# MB9BF56xx register map
File version: 1.0
Registers are 8-bit, read-write, reset 0x0 unless marked. A register's access mark holds for its fields unless they carry their own. Offsets are from the block's base; [hi:lo] are bit positions; {n}, {i} and the like mark numbered series; 'fields as' and 'values as' point back to an identical list.

## MFT0 — peripheral MFT0
Base 0x40020000
Same registers: MFT1 0x40021000, MFT2 0x40022000
{0x102+4i} OCU_OCCP{i} 16-bit (i=0..5)
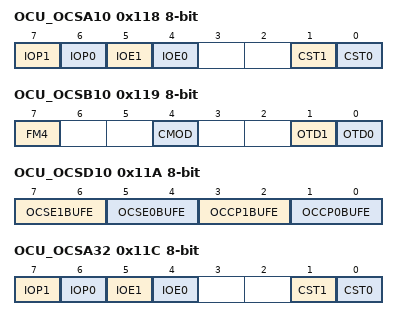
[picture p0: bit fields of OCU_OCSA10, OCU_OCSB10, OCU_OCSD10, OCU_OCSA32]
0x118 OCU_OCSA10
  [7] IOP1, [6] IOP0, [5] IOE1, [4] IOE0, [1] CST1, [0] CST0
0x119 OCU_OCSB10
  [7] FM4, [4] CMOD, [1] OTD1, [0] OTD0
0x11A OCU_OCSD10
  [7:6] OCSE1BUFE, [5:4] OCSE0BUFE, [3:2] OCCP1BUFE, [1:0] OCCP0BUFE
0x11C OCU_OCSA32
  [7] IOP1, [6] IOP0, [5] IOE1, [4] IOE0, [1] CST1, [0] CST0
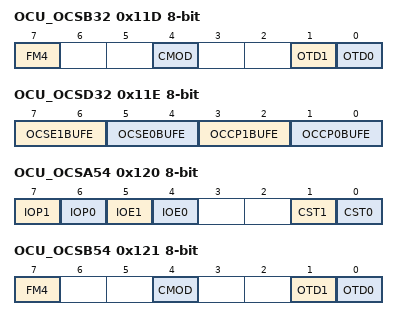
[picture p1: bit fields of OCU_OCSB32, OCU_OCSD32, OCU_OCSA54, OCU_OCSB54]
0x11D OCU_OCSB32
  [7] FM4, [4] CMOD, [1] OTD1, [0] OTD0
0x11E OCU_OCSD32
  [7:6] OCSE1BUFE, [5:4] OCSE0BUFE, [3:2] OCCP1BUFE, [1:0] OCCP0BUFE
0x120 OCU_OCSA54
  [7] IOP1, [6] IOP0, [5] IOE1, [4] IOE0, [1] CST1, [0] CST0
0x121 OCU_OCSB54
  [7] FM4, [4] CMOD, [1] OTD1, [0] OTD0
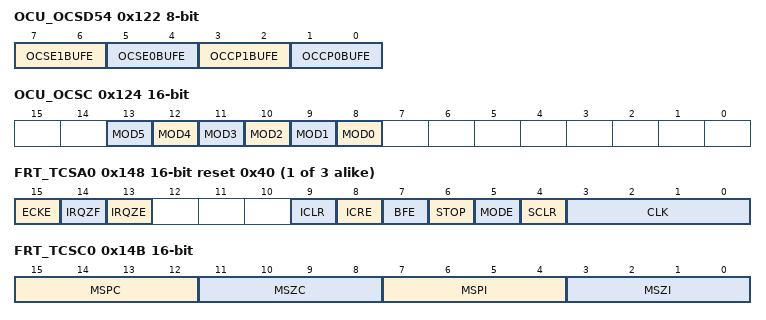
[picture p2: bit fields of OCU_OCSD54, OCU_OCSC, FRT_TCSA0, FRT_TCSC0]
0x122 OCU_OCSD54
  [7:6] OCSE1BUFE, [5:4] OCSE0BUFE, [3:2] OCCP1BUFE, [1:0] OCCP0BUFE
0x124 OCU_OCSC 16-bit
  [n+8] MOD{n} (n=0..5)
0x128 OCU_OCSE0
  [7:0] OCSE
0x12C OCU_OCSE1 16-bit
  [15:0] OCSE
0x130 OCU_OCSE2
  [7:0] OCSE
0x134 OCU_OCSE3 16-bit
  [15:0] OCSE
0x138 OCU_OCSE4
  [7:0] OCSE
0x13C OCU_OCSE5 16-bit
  [15:0] OCSE
{0x142+0xC*i} FRT_TCCP{i} 16-bit reset 0xFFFF (i=0..2)
{0x146+0xC*i} FRT_TCDT{i} 16-bit (i=0..2)
{0x148+0xC*i} FRT_TCSA{i} 16-bit reset 0x40 (i=0..2)
  [15] ECKE, [14] IRQZF, [13] IRQZE, [9] ICLR, [8] ICRE, [7] BFE, [6] STOP, [5] MODE, [4] SCLR wo, [3:0] CLK
0x14B FRT_TCSC0 16-bit
  [15:12] MSPC ro, [11:8] MSZC ro, [7:4] MSPI, [3:0] MSZI
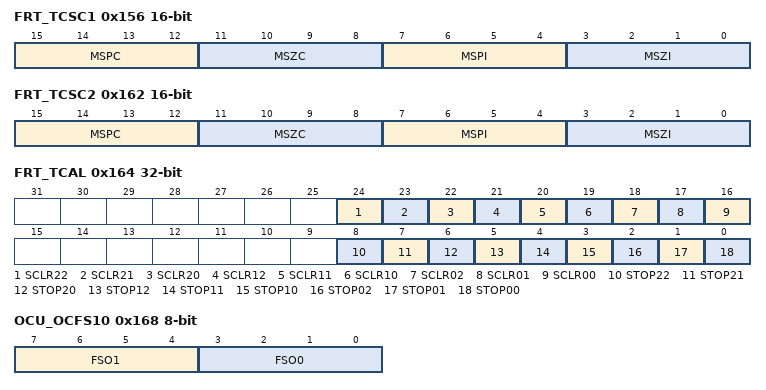
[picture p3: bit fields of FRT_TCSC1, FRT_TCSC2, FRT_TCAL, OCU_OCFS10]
0x156 FRT_TCSC1 16-bit
  [15:12] MSPC ro, [11:8] MSZC ro, [7:4] MSPI, [3:0] MSZI
0x162 FRT_TCSC2 16-bit
  [15:12] MSPC ro, [11:8] MSZC ro, [7:4] MSPI, [3:0] MSZI
0x164 FRT_TCAL 32-bit (reset mask 0xFFFF)
  [24] SCLR22 wo, [23] SCLR21 wo, [22] SCLR20 wo, [21] SCLR12 wo, [20] SCLR11 wo, [19] SCLR10 wo, [18] SCLR02 wo, [17] SCLR01 wo, [16] SCLR00 wo, [8] STOP22, [7] STOP21, [6] STOP20, [5] STOP12, [4] STOP11, [3] STOP10, [2] STOP02, [1] STOP01, [0] STOP00
0x168 OCU_OCFS10
  [7:4] FSO1, [3:0] FSO0
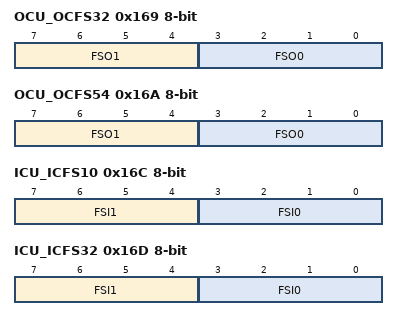
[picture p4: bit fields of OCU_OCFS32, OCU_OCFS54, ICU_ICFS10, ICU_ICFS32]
0x169 OCU_OCFS32
  [7:4] FSO1, [3:0] FSO0
0x16A OCU_OCFS54
  [7:4] FSO1, [3:0] FSO0
0x16C ICU_ICFS10
  [7:4] FSI1, [3:0] FSI0
0x16D ICU_ICFS32
  [7:4] FSI1, [3:0] FSI0
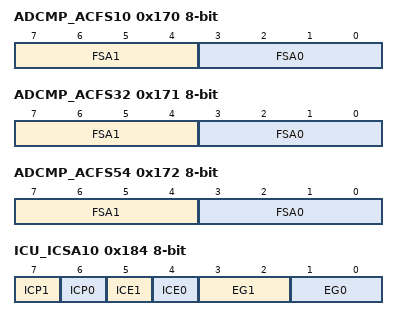
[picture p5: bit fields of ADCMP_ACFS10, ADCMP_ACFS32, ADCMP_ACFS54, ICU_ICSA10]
0x170 ADCMP_ACFS10
  [7:4] FSA1, [3:0] FSA0
0x171 ADCMP_ACFS32
  [7:4] FSA1, [3:0] FSA0
0x172 ADCMP_ACFS54
  [7:4] FSA1, [3:0] FSA0
{0x176+4i} ICU_ICCP{i} 16-bit ro reset not defined (i=0..3)
0x184 ICU_ICSA10
  [7] ICP1, [6] ICP0, [5] ICE1, [4] ICE0, [3:2] EG1, [1:0] EG0
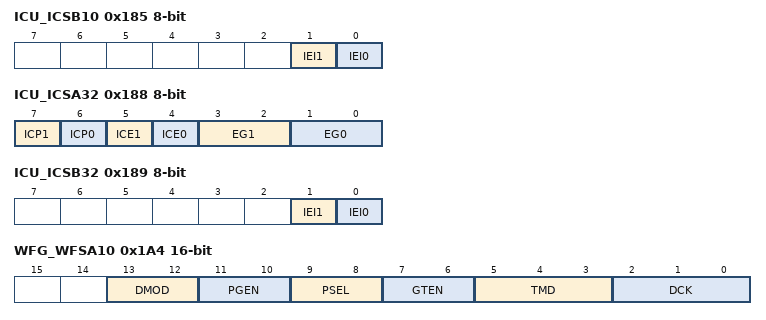
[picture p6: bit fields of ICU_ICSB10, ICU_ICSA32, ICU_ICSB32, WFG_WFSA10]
0x185 ICU_ICSB10 ro
  [1] IEI1, [0] IEI0
0x188 ICU_ICSA32
  [7] ICP1, [6] ICP0, [5] ICE1, [4] ICE0, [3:2] EG1, [1:0] EG0
0x189 ICU_ICSB32 ro
  [1] IEI1, [0] IEI0
0x18E WFG_WFTF10 16-bit
0x190 WFG_WFTA10
0x192 WFG_WFTB10
0x196 WFG_WFTF32 16-bit
0x198 WFG_WFTA32
0x19A WFG_WFTB32
0x19E WFG_WFTF54 16-bit
0x1A0 WFG_WFTA54
0x1A2 WFG_WFTB54
0x1A4 WFG_WFSA10 16-bit
  [13:12] DMOD, [11:10] PGEN, [9:8] PSEL, [7:6] GTEN, [5:3] TMD, [2:0] DCK
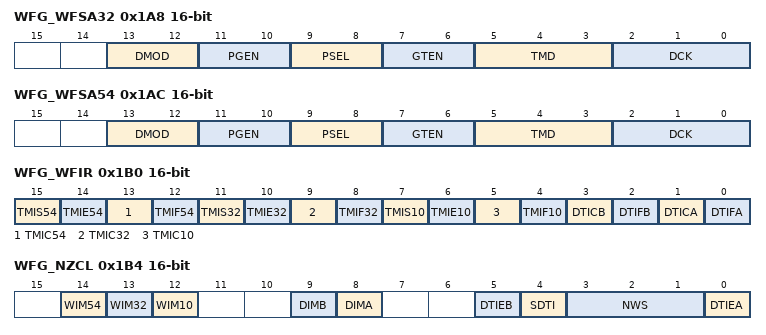
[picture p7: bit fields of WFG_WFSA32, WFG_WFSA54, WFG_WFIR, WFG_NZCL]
0x1A8 WFG_WFSA32 16-bit
  fields as WFG_WFSA10
0x1AC WFG_WFSA54 16-bit
  fields as WFG_WFSA10
0x1B0 WFG_WFIR 16-bit
  [15] TMIS54 wo, [14] TMIE54, [13] TMIC54 wo, [12] TMIF54 ro, [11] TMIS32 wo, [10] TMIE32, [9] TMIC32 wo, [8] TMIF32 ro, [7] TMIS10 wo, [6] TMIE10, [5] TMIC10 wo, [4] TMIF10 ro, [3] DTICB wo, [2] DTIFB ro, [1] DTICA wo, [0] DTIFA ro
0x1B4 WFG_NZCL 16-bit
  [14] WIM54, [13] WIM32, [12] WIM10, [9] DIMB, [8] DIMA, [5] DTIEB, [4] SDTI wo, [3:1] NWS, [0] DTIEA
{0x1BA+4i} ADCMP_ACMP{i} 16-bit (i=0..5)
  [15:0] ACMP
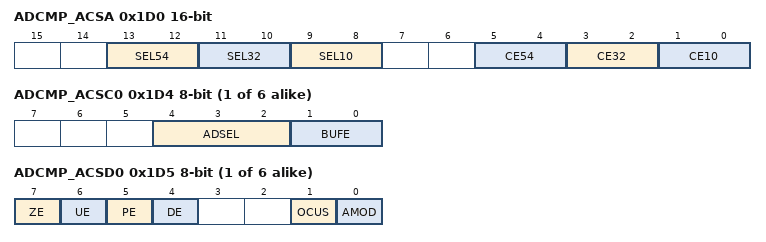
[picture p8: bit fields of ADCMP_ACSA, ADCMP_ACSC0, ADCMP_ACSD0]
0x1D0 ADCMP_ACSA 16-bit
  [13:12] SEL54, [11:10] SEL32, [9:8] SEL10, [5:4] CE54, [3:2] CE32, [1:0] CE10
{0x1D4+4i} ADCMP_ACSC{i} (i=0..5)
  [4:2] ADSEL, [1:0] BUFE
{0x1D5+4i} ADCMP_ACSD{i} (i=0..5)
  [7] ZE, [6] UE, [5] PE, [4] DE, [1] OCUS, [0] AMOD

## BTIOSEL03 — peripheral BTIOSEL03
Base 0x40025100
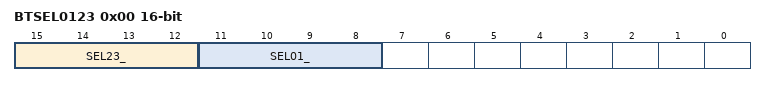
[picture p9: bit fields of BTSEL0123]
0x00 BTSEL0123 16-bit
  [15:12] SEL23_, [11:8] SEL01_

## BTIOSEL47 — peripheral BTIOSEL47
Base 0x40025300
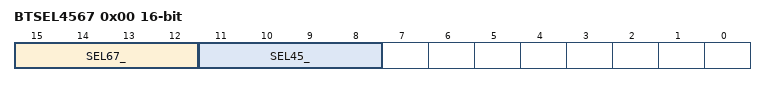
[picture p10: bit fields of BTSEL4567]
0x00 BTSEL4567 16-bit
  [15:12] SEL67_, [11:8] SEL45_

## Notices in the file
Licence Terms
FUJITSU SEMICONDUCTOR LIMITED (gLICENSORh) hereby grants and
you (gLICENSEEh) hereby accept a non transferable, non-exclusive
licence to use and copy the deliverables (gDeliverablesh) solely for
the purpose of; (i) developing LICENSEEfs development tools and
distributing such development tools to third parties; (ii) generating
derivative representations of the Deliverables to develop and debug
software for LICENSORfs targeted devices or device series identified
within the Deliverables, (together the gPurposeh) under the following
terms and conditions:
1. Ownership.
The Deliverables are the property of LICENSOR. LICENSEE acquires no
right, title or interest in the Deliverables other than the licence
rights granted herein.
2. Use.
LICENSEE shall only be permitted to use the Deliverables for the
Purpose. LICENSEE shall not reverse engineer, decompile or
disassemble the Deliverables, in whole or in part.
3. Copies.
All copies of the Deliverables must bear the same notice(s) contained
on the original copies of the Deliverables.
4. No Warranty.
THE DELIVERABLES ARE PROVIDED gAS ISh AND ANY EXPRESS, IMPLIED OR
STATUTORY WARRANTIES, INCLUDING, BUT NOT LIMITED TO, THE IMPLIED
WARRANTIES OF MERCHANTABILITY, SATISFACTORY QUALITY AND FITNESS FOR
A PARTICULAR PURPOSE ARE DISCLAIMED.
IN NO EVENT SHALL LICENSOR BE LIABLE FOR ANY DIRECT, INDIRECT,
INCIDENTAL, SPECIAL, EXEMPLARY, OR CONSEQUENTIAL DAMAGES HOWEVER CAUSED
AND ON ANY THEORY OF LIABILITY, WHETHER IN CONTRACT, STRICT LIABILITY,
OR TORT (INCLUDING NEGLIGENCE OR OTHERWISE) ARISING IN ANY WAY OUT OF
THE USE OF THE DELIVERABLES, EVEN IF ADVISED OF THE POSSIBILITY OF SUCH
DAMAGE.
LICENSEE EXPRESSLY ASSUMES ALL LIABILITIES AND RISKS, FOR USE OR
OPERATION OF THE DELIVERABLES.
5.In the event that LICENSEE receives early access to the Deliverables,
LICENSEE acknowledges and agrees that;
(a) notwithstanding the licence grants above, LICENSEE shall only be
permitted to use the Deliverables solely internally for evaluation and
providing feedback to LICENSOR;
(b) except with respect to the limited licence grants in 5(a), LICENSEE
shall be subject to all of the terms and conditions set out above; and
(c) the Deliverables are confidential information and LICENSEE shall
maintain in confidence the Deliverables and apply security measures no
less stringent than the measures that LICENSEE applies to its own like
information, but not less than a reasonable degree of care, to prevent
unauthorised disclosure and use of the Deliverables.
